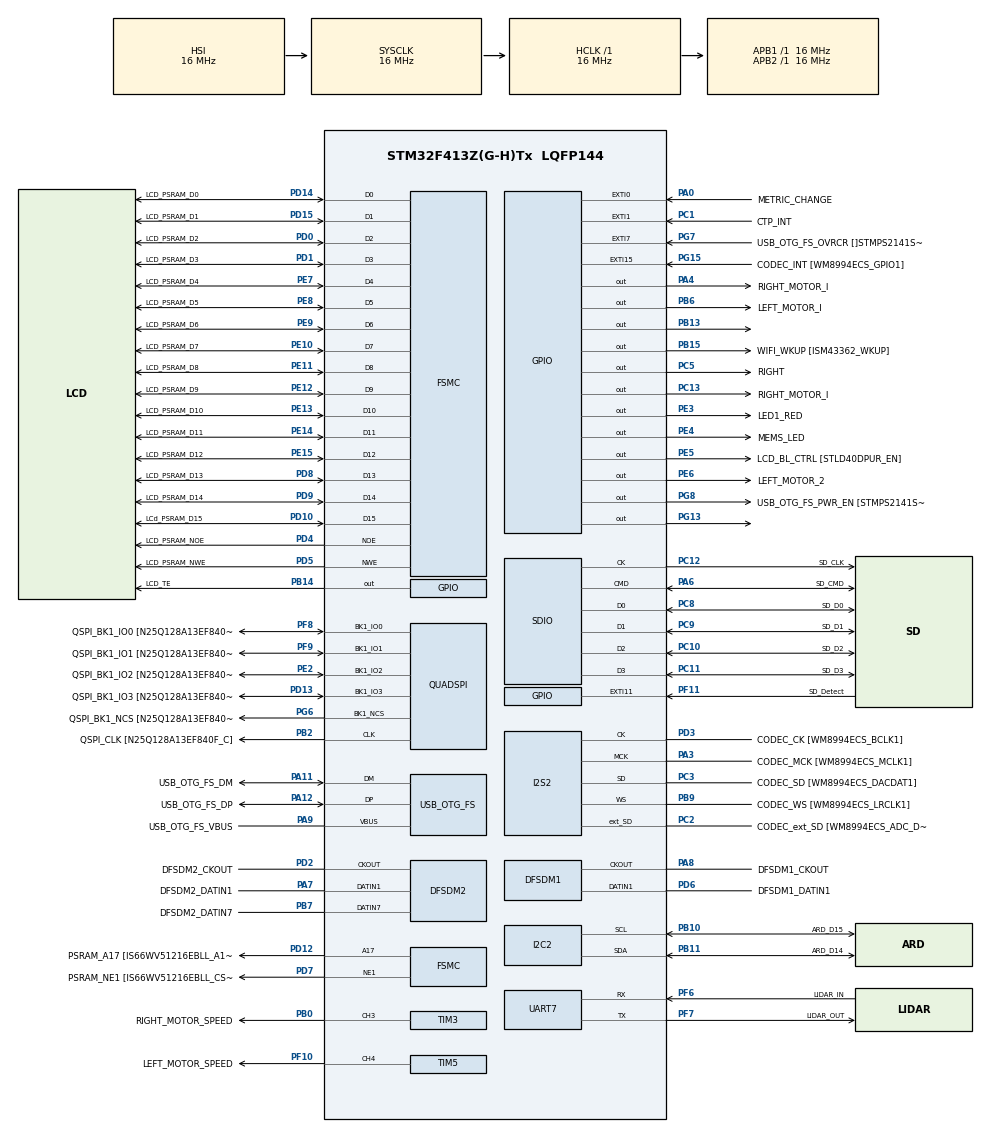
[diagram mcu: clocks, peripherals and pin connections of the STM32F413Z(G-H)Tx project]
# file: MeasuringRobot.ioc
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Dma.Request0=UART7_RX
Dma.UART7_RX.0.Direction=DMA_PERIPH_TO_MEMORY
Dma.UART7_RX.0.FIFOMode=DMA_FIFOMODE_DISABLE
Dma.UART7_RX.0.Instance=DMA1_Stream3
Dma.UART7_RX.0.MemDataAlignment=DMA_MDATAALIGN_BYTE
Dma.UART7_RX.0.MemInc=DMA_MINC_ENABLE
Dma.UART7_RX.0.Mode=DMA_NORMAL
Dma.UART7_RX.0.PeriphDataAlignment=DMA_PDATAALIGN_BYTE
Dma.UART7_RX.0.PeriphInc=DMA_PINC_DISABLE
Dma.UART7_RX.0.Priority=DMA_PRIORITY_LOW
FREERTOS.Tasks01=MetricChange,24,128,MetricChangeTask,Default,NULL,Dynamic,NULL,NULL;Motor,24,128,MotorTask,Default,NULL,Dynamic,NULL,NULL;Lidar,24,128,LidarTask,Default,NULL,Dynamic,NULL,NULL;LCD,24,128,LCDTask,Default,NULL,Dynamic,NULL,NULL
I2S2.ErrorAudioFreq=1.72 %
I2S2.FullDuplexMode=I2S_FULLDUPLEXMODE_ENABLE
I2S2.Instance=SPI$Index
I2S2.RealAudioFreq=8.138 KHz
I2S2.VirtualMode=I2S_MODE_MASTER
Mcu.Family=STM32F4
Mcu.Name=STM32F413Z(G-H)Tx
Mcu.Package=LQFP144
NVIC.DMA1_Stream3_IRQn=true\:0\:0\:false\:false\:true\:true\:false\:true
NVIC.EXTI0_IRQn=true\:0\:0\:false\:false\:true\:false\:true\:true
NVIC.OTG_FS_IRQn=true\:0\:0\:false\:false\:true\:false\:true\:true
NVIC.PriorityGroup=NVIC_PRIORITYGROUP_4
NVIC.TIM6_DAC_IRQn=true\:0\:0\:false\:false\:true\:false\:false\:true
NVIC.TimeBase=TIM6_DAC_IRQn
NVIC.TimeBaseIP=TIM6
PA0.GPIO_Label=METRIC_CHANGE
PA0.Signal=GPXTI0
PA10.GPIO_Label=USB_OTG_FS_ID
PA10.Signal=USB_OTG_FS_ID
PA11.GPIO_Label=USB_OTG_FS_DM
PA11.Mode=Host_Only
PA11.Signal=USB_OTG_FS_DM
PA12.GPIO_Label=USB_OTG_FS_DP
PA12.Mode=Host_Only
PA12.Signal=USB_OTG_FS_DP
PA13.GPIO_Label=STLINK_JTMS_SWDIO
PA13.Mode=Serial_Wire
PA13.Signal=SYS_JTMS-SWDIO
PA14.GPIO_Label=STLINK_JTMS_SWCLK
PA14.Mode=Serial_Wire
PA14.Signal=SYS_JTCK-SWCLK
PA15.GPIO_Label=ARD_D10
PA15.Signal=S_TIM2_CH1_ETR
PA3.GPIO_Label=CODEC_MCK [WM8994ECS_MCLK1]
PA3.Mode=Master_Clock_Activated
PA3.Signal=I2S2_MCK
PA4.GPIO_Label=RIGHT_MOTOR_I
PA4.Signal=GPIO_Output
PA5.GPIO_Label=ARD_A3
PA5.Signal=ADCx_IN5
PA6.GPIO_Label=SD_CMD
PA6.Mode=SD_4_bits_Wide_bus
PA6.Signal=SDIO_CMD
PA7.GPIO_Label=DFSDM2_DATIN1
PA7.Signal=S_DATAIN1DFSDM2
PA8.GPIO_Label=DFSDM1_CKOUT
PA8.Signal=S_CKOUTDFSDM1
PA9.GPIO_Label=USB_OTG_FS_VBUS
PA9.Mode=Activate_VBUS
PA9.Signal=USB_OTG_FS_VBUS
PB0.GPIO_Label=RIGHT_MOTOR_SPEED
PB0.Signal=S_TIM3_CH3
PB1.GPIO_Label=ARD_A4
PB1.Signal=ADCx_IN9
PB10.GPIO_Label=ARD_D15
PB10.Mode=I2C
PB10.Signal=I2C2_SCL
PB11.GPIO_Label=ARD_D14
PB11.Mode=I2C
PB11.Signal=I2C2_SDA
PB12.GPIO_Label=ARD_D13 [ISM43362_SCK]
PB12.Signal=SPI3_SCK
PB13.Signal=GPIO_Output
PB14.GPIO_Label=LCD_TE
PB14.Signal=GPIO_Output
PB15.GPIO_Label=WIFI_WKUP [ISM43362_WKUP]
PB15.Signal=GPIO_Output
PB2.GPIO_Label=QSPI_CLK [N25Q128A13EF840F_C]
PB2.Mode=Single Bank 1
PB2.Signal=QUADSPI_CLK
PB3.GPIO_Label=STLINK_JTDO_SWCLK
PB3.Signal=SYS_JTDO-SWO
PB4.GPIO_Label=ARD_D12 [ISM43362_MISO]
PB4.Signal=SPI3_MISO
PB5.GPIO_Label=ARD_D11 [ISM43362_MOSI]
PB5.Signal=SPI3_MOSI
PB6.GPIO_Label=LEFT_MOTOR_I
PB6.Signal=GPIO_Output
PB7.GPIO_Label=DFSDM2_DATIN7
PB7.Signal=S_DATAIN7DFSDM2
PB8.GPIO_Label=ARD_D9
PB8.Signal=S_TIM4_CH3
PB9.GPIO_Label=CODEC_WS [WM8994ECS_LRCLK1]
PB9.Mode=Full_Duplex_Master
PB9.Signal=I2S2_WS
PC0.GPIO_Label=ARD_A0
PC0.Signal=ADCx_IN10
PC1.GPIO_Label=CTP_INT
PC1.Signal=GPXTI1
PC10.GPIO_Label=SD_D2
PC10.Mode=SD_4_bits_Wide_bus
PC10.Signal=SDIO_D2
PC11.GPIO_Label=SD_D3
PC11.Mode=SD_4_bits_Wide_bus
PC11.Signal=SDIO_D3
PC12.GPIO_Label=SD_CLK
PC12.Mode=SD_4_bits_Wide_bus
PC12.Signal=SDIO_CK
PC13.GPIO_Label=RIGHT_MOTOR_I
PC13.Signal=GPIO_Output
PC14-OSC32_IN.GPIO_Label=OSC32_IN
PC14-OSC32_IN.Mode=LSE-External-Oscillator
PC14-OSC32_IN.Signal=RCC_OSC32_IN
PC15-OSC32_OUT.GPIO_Label=OSC32_OUT
PC15-OSC32_OUT.Mode=LSE-External-Oscillator
PC15-OSC32_OUT.Signal=RCC_OSC32_OUT
PC2.GPIO_Label=CODEC_ext_SD [WM8994ECS_ADC_DAT1]
PC2.Mode=Full_Duplex_Master
PC2.Signal=I2S2_ext_SD
PC3.GPIO_Label=CODEC_SD [WM8994ECS_DACDAT1]
PC3.Mode=Full_Duplex_Master
PC3.Signal=I2S2_SD
PC4.GPIO_Label=ARD_A5
PC4.Signal=ADCx_IN14
PC5.GPIO_Label=RIGHT
PC5.Signal=GPIO_Output
PC6.GPIO_Label=I2CFMP1_SCL [WM8994ECS_CLK]
PC6.Signal=FMPI2C1_SCL
PC7.GPIO_Label=I2CFMP_SDA [WM8994ECS_SDA]
PC7.Signal=FMPI2C1_SDA
PC8.GPIO_Label=SD_D0
PC8.Mode=SD_4_bits_Wide_bus
PC8.Signal=SDIO_D0
PC9.GPIO_Label=SD_D1
PC9.Mode=SD_4_bits_Wide_bus
PC9.Signal=SDIO_D1
PD0.GPIO_Label=LCD_PSRAM_D2
PD0.Signal=FSMC_D2_DA2
PD1.GPIO_Label=LCD_PSRAM_D3
PD1.Signal=FSMC_D3_DA3
PD10.GPIO_Label=LCd_PSRAM_D15
PD10.Signal=FSMC_D15_DA15
PD11.GPIO_Label=PSRAM_A16 [IS66WV51216EBLL_A16]
PD11.Signal=FSMC_A16
PD12.GPIO_Label=PSRAM_A17 [IS66WV51216EBLL_A17]
PD12.Signal=FSMC_A17
PD13.GPIO_Label=QSPI_BK1_IO3 [N25Q128A13EF840F_DQ3]
PD13.Mode=Single Bank 1
PD13.Signal=QUADSPI_BK1_IO3
PD14.GPIO_Label=LCD_PSRAM_D0
PD14.Signal=FSMC_D0_DA0
PD15.GPIO_Label=LCD_PSRAM_D1
PD15.Signal=FSMC_D1_DA1
PD2.GPIO_Label=DFSDM2_CKOUT
PD2.Signal=S_CKOUTDFSDM2
PD3.GPIO_Label=CODEC_CK [WM8994ECS_BCLK1]
PD3.Mode=Full_Duplex_Master
PD3.Signal=I2S2_CK
PD4.GPIO_Label=LCD_PSRAM_NOE
PD4.Signal=FSMC_NOE
PD5.GPIO_Label=LCD_PSRAM_NWE
PD5.Signal=FSMC_NWE
PD6.GPIO_Label=DFSDM1_DATIN1
PD6.Signal=S_DATAIN1DFSDM1
PD7.GPIO_Label=PSRAM_NE1 [IS66WV51216EBLL_CS1]
PD7.Mode=NorPsramChipSelect1_1
PD7.Signal=FSMC_NE1
PD8.GPIO_Label=LCD_PSRAM_D13
PD8.Signal=FSMC_D13_DA13
PD9.GPIO_Label=LCD_PSRAM_D14
PD9.Signal=FSMC_D14_DA14
PE0.GPIO_Label=PSRAM_NBL0 [IS66WV51216EBLL_LB]
PE0.Signal=FSMC_NBL0
PE1.GPIO_Label=PSRAM_NBL1 [IS66WV51216EBLL_UB]
PE1.Signal=FSMC_NBL1
PE10.GPIO_Label=LCD_PSRAM_D7
PE10.Signal=FSMC_D7_DA7
PE11.GPIO_Label=LCD_PSRAM_D8
PE11.Signal=FSMC_D8_DA8
PE12.GPIO_Label=LCD_PSRAM_D9
PE12.Signal=FSMC_D9_DA9
PE13.GPIO_Label=LCD_PSRAM_D10
PE13.Signal=FSMC_D10_DA10
PE14.GPIO_Label=LCD_PSRAM_D11
PE14.Signal=FSMC_D11_DA11
PE15.GPIO_Label=LCD_PSRAM_D12
PE15.Signal=FSMC_D12_DA12
PE2.GPIO_Label=QSPI_BK1_IO2 [N25Q128A13EF840F_DQ2]
PE2.Mode=Single Bank 1
PE2.Signal=QUADSPI_BK1_IO2
PE3.GPIO_Label=LED1_RED
PE3.Signal=GPIO_Output
PE4.GPIO_Label=MEMS_LED
PE4.Signal=GPIO_Output
PE5.GPIO_Label=LCD_BL_CTRL [STLD40DPUR_EN]
PE5.Signal=GPIO_Output
PE6.GPIO_Label=LEFT_MOTOR_2
PE6.Signal=GPIO_Output
PE7.GPIO_Label=LCD_PSRAM_D4
PE7.Signal=FSMC_D4_DA4
PE8.GPIO_Label=LCD_PSRAM_D5
PE8.Signal=FSMC_D5_DA5
PE9.GPIO_Label=LCD_PSRAM_D6
PE9.Signal=FSMC_D6_DA6
PF0.GPIO_Label=PSRAM_A0 [IS66WV51216EBLL_A0]
PF0.Signal=FSMC_A0
PF1.GPIO_Label=PSRAM_A1 [IS66WV51216EBLL_A1]
PF1.Signal=FSMC_A1
PF10.GPIO_Label=LEFT_MOTOR_SPEED
PF10.Signal=S_TIM5_CH4
PF11.GPIO_Label=SD_Detect
PF11.Signal=GPXTI11
PF12.GPIO_Label=PSRAM_A6 [IS66WV51216EBLL_A6]
PF12.Signal=FSMC_A6
PF13.GPIO_Label=PSRAM_A7 [IS66WV51216EBLL_A7]
PF13.Signal=FSMC_A7
PF14.GPIO_Label=PSRAM_A8 [IS66WV51216EBLL_A8]
PF14.Signal=FSMC_A8
PF15.GPIO_Label=PSRAM_A9 [IS66WV51216EBLL_A9]
PF15.Signal=FSMC_A9
PF2.GPIO_Label=PSRAM_A2 [IS66WV51216EBLL_A2]
PF2.Signal=FSMC_A2
PF3.GPIO_Label=PSRAM_A3 [IS66WV51216EBLL_A3]
PF3.Signal=FSMC_A3
PF4.GPIO_Label=PSRAM_A4 [IS66WV51216EBLL_A4]
PF4.Signal=FSMC_A4
PF5.GPIO_Label=PSRAM_A5 [IS66WV51216EBLL_A5]
PF5.Signal=FSMC_A5
PF6.GPIO_Label=LIDAR_IN
PF6.Mode=Asynchronous
PF6.Signal=UART7_RX
PF7.GPIO_Label=LIDAR_OUT
PF7.Mode=Asynchronous
PF7.Signal=UART7_TX
PF8.GPIO_Label=QSPI_BK1_IO0 [N25Q128A13EF840F_DQ0]
PF8.Mode=Single Bank 1
PF8.Signal=QUADSPI_BK1_IO0
PF9.GPIO_Label=QSPI_BK1_IO1 [N25Q128A13EF840F_DQ1]
PF9.Mode=Single Bank 1
PF9.Signal=QUADSPI_BK1_IO1
PG0.GPIO_Label=PSRAM_A10 [IS66WV51216EBLL_A10]
PG0.Signal=FSMC_A10
PG1.GPIO_Label=PSRAM_A11 [IS66WV51216EBLL_A11]
PG1.Signal=FSMC_A11
PG13.Signal=GPIO_Output
PG14.Signal=USART6_TX
PG15.GPIO_Label=CODEC_INT [WM8994ECS_GPIO1]
PG15.Signal=GPXTI15
PG2.GPIO_Label=PSRAM_A12 [IS66WV51216EBLL_A12]
PG2.Signal=FSMC_A12
PG3.GPIO_Label=PSRAM_A13 [IS66WV51216EBLL_A13]
PG3.Signal=FSMC_A13
PG4.GPIO_Label=PSRAM_A14 [IS66WV51216EBLL_A14]
PG4.Signal=FSMC_A14
PG5.GPIO_Label=PSRAM_A15 [IS66WV51216EBLL_A15]
PG5.Signal=FSMC_A15
PG6.GPIO_Label=QSPI_BK1_NCS [N25Q128A13EF840F_S]
PG6.Mode=Single Bank 1
PG6.Signal=QUADSPI_BK1_NCS
PG7.GPIO_Label=USB_OTG_FS_OVRCR []STMPS2141STR_FAULT]
PG7.Signal=GPXTI7
PG8.GPIO_Label=USB_OTG_FS_PWR_EN [STMPS2141STR_EN]
PG8.Signal=GPIO_Output
PG9.Signal=USART6_RX
PH0\ -\ OSC_IN.GPIO_Label=STLK_MCO
PH0\ -\ OSC_IN.Mode=HSE-External-Oscillator
PH0\ -\ OSC_IN.Signal=RCC_OSC_IN
PH1\ -\ OSC_OUT.Mode=HSE-External-Oscillator
PH1\ -\ OSC_OUT.Signal=RCC_OSC_OUT
ProjectManager.HeapSize=0x200
ProjectManager.StackSize=0x400
ProjectManager.TargetToolchain=STM32CubeIDE
RCC.AHBFreq_Value=16000000
RCC.APB1Freq_Value=16000000
RCC.APB1TimFreq_Value=16000000
RCC.APB2Freq_Value=16000000
RCC.APB2TimFreq_Value=16000000
RCC.CortexFreq_Value=16000000
RCC.HCLKFreq_Value=16000000
RCC.PLLI2SM=12
RCC.PLLI2SN=50
RCC.PLLM=15
RCC.PLLN=144
RCC.PLLQ=5
RCC.SDIOCLockSelection=RCC_SDIOCLKSOURCE_SYSCLK
RCC.SYSCLKFreq_VALUE=16000000
RCC.USBFreq_Value=48000000
RCC.VCOOutputFreq_Value=240000000
SH.ADCx_IN10.0=ADC1_IN10
SH.ADCx_IN14.0=ADC1_IN14
SH.ADCx_IN5.0=ADC1_IN5
SH.ADCx_IN9.0=ADC1_IN9
SH.FSMC_A0.0=FSMC_A0
SH.FSMC_A1.0=FSMC_A1
SH.FSMC_A10.0=FSMC_A10
SH.FSMC_A11.0=FSMC_A11
SH.FSMC_A12.0=FSMC_A12
SH.FSMC_A13.0=FSMC_A13
SH.FSMC_A14.0=FSMC_A14
SH.FSMC_A15.0=FSMC_A15
SH.FSMC_A16.0=FSMC_A16
SH.FSMC_A17.0=FSMC_A17,A17_1
SH.FSMC_A2.0=FSMC_A2
SH.FSMC_A3.0=FSMC_A3
SH.FSMC_A4.0=FSMC_A4
SH.FSMC_A5.0=FSMC_A5
SH.FSMC_A6.0=FSMC_A6
SH.FSMC_A7.0=FSMC_A7
SH.FSMC_A8.0=FSMC_A8
SH.FSMC_A9.0=FSMC_A9
SH.FSMC_D0_DA0.0=FSMC_D0,16b-d1
SH.FSMC_D10_DA10.0=FSMC_D10,16b-d1
SH.FSMC_D11_DA11.0=FSMC_D11,16b-d1
SH.FSMC_D12_DA12.0=FSMC_D12,16b-d1
SH.FSMC_D13_DA13.0=FSMC_D13,16b-d1
SH.FSMC_D14_DA14.0=FSMC_D14,16b-d1
SH.FSMC_D15_DA15.0=FSMC_D15,16b-d1
SH.FSMC_D1_DA1.0=FSMC_D1,16b-d1
SH.FSMC_D2_DA2.0=FSMC_D2,16b-d1
SH.FSMC_D3_DA3.0=FSMC_D3,16b-d1
SH.FSMC_D4_DA4.0=FSMC_D4,16b-d1
SH.FSMC_D5_DA5.0=FSMC_D5,16b-d1
SH.FSMC_D6_DA6.0=FSMC_D6,16b-d1
SH.FSMC_D7_DA7.0=FSMC_D7,16b-d1
SH.FSMC_D8_DA8.0=FSMC_D8,16b-d1
SH.FSMC_D9_DA9.0=FSMC_D9,16b-d1
SH.FSMC_NBL0.0=FSMC_NBL0
SH.FSMC_NBL1.0=FSMC_NBL1
SH.FSMC_NOE.0=FSMC_NOE,Lcd1
SH.FSMC_NWE.0=FSMC_NWE,Lcd1
SH.S_CKOUTDFSDM1.0=DFSDM1_CKOUT,CKOUT
SH.S_CKOUTDFSDM2.0=DFSDM2_CKOUT,CKOUT
SH.S_DATAIN1DFSDM1.0=DFSDM1_DATIN1,Manchester_input_from_ch1
SH.S_DATAIN1DFSDM2.0=DFSDM2_DATIN1,Manchester_input_from_ch1
SH.S_DATAIN7DFSDM2.0=DFSDM2_DATIN7,Manchester_input_from_ch7
SH.S_TIM2_CH1_ETR.0=TIM2_CH1
SH.S_TIM3_CH3.0=TIM3_CH3,PWM Generation3 CH3
SH.S_TIM4_CH3.0=TIM4_CH3
SH.S_TIM5_CH4.0=TIM5_CH4,PWM Generation4 CH4
TIM3.Channel-PWM\ Generation3\ CH3=TIM_CHANNEL_3
TIM3.Period=1000
TIM3.Prescaler=16
TIM3.Pulse-PWM\ Generation3\ CH3=500
TIM5.Channel-PWM\ Generation4\ CH4=TIM_CHANNEL_4
TIM5.Period=1000
TIM5.Prescaler=16
TIM5.Pulse-PWM\ Generation4\ CH4=500
UART7.OverSampling=UART_OVERSAMPLING_16
UART7.VirtualMode=Asynchronous
UART7.WordLength=WORDLENGTH_8B
USB_HOST.BSP.number=1
USB_HOST.USBH_HandleTypeDef=hUsbHostFS
USB_HOST.USBH_USE_OS-CDC_FS=0
USB_HOST.VirtualModeFS=Cdc
USB_HOST0.BSP.STBoard=false
USB_HOST0.BSP.api=Unknown
USB_HOST0.BSP.i2caddr=0
USB_HOST0.BSP.i2creg=0
USB_HOST0.BSP.instance=PG8
USB_HOST0.BSP.ip=GPIO
USB_HOST0.BSP.mode=Output
USB_HOST0.BSP.name=Drive_VBUS_FS
USB_HOST0.BSP.solution=PG8
USB_OTG_FS.VirtualMode=Host_Only
USB_OTG_FS.phy_itface=HCD_PHY_EMBEDDED
VP_FREERTOS_VS_CMSIS_V2.Mode=CMSIS_V2
VP_SYS_VS_tim6.Mode=TIM6
VP_TIM3_VS_ClockSourceINT.Mode=Internal
VP_TIM5_VS_ClockSourceINT.Mode=Internal
VP_USB_HOST_VS_USB_HOST_CDC_FS.Mode=CDC_FS
board=STM32F413H-DISCO

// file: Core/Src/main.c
/* USER CODE BEGIN Header */
/**
 ******************************************************************************
 * @file           : main.c
 * @brief          : Main program body
 ******************************************************************************
 * @attention
 *
 * <h2><center>&copy; Copyright (c) 2022 STMicroelectronics.
 * All rights reserved.</center></h2>
 *
 * This software component is licensed by ST under Ultimate Liberty license
 * SLA0044, the "License"; You may not use this file except in compliance with
 * the License. You may obtain a copy of the License at:
 *                             www.st.com/SLA0044
 *
 ******************************************************************************
 */
/* USER CODE END Header */
#include "main.h"
#include "cmsis_os.h"
#include "usb_host.h"

/* USER CODE BEGIN Includes */
#include "stm32F413h_discovery_lcd.h"
#include "math.h"
#include "stdlib.h"
#include "stdio.h"
/* USER CODE END Includes */

DFSDM_Channel_HandleTypeDef hdfsdm1_channel1;
DFSDM_Channel_HandleTypeDef hdfsdm2_channel1;
DFSDM_Channel_HandleTypeDef hdfsdm2_channel7;

I2C_HandleTypeDef hi2c2;

I2S_HandleTypeDef hi2s2;

QSPI_HandleTypeDef hqspi;

SD_HandleTypeDef hsd;

TIM_HandleTypeDef htim3;
TIM_HandleTypeDef htim5;

UART_HandleTypeDef huart7;
DMA_HandleTypeDef hdma_uart7_rx;

SRAM_HandleTypeDef hsram1;

/* Definitions for MetricChange */
osThreadId_t MetricChangeHandle;
const osThreadAttr_t MetricChange_attributes = { .name = "MetricChange",
		.priority = (osPriority_t) osPriorityNormal, .stack_size = 128 * 4 };
/* Definitions for Motor */
osThreadId_t MotorHandle;
const osThreadAttr_t Motor_attributes = { .name = "Motor", .priority =
		(osPriority_t) osPriorityNormal, .stack_size = 128 * 4 };
/* Definitions for Lidar */
osThreadId_t LidarHandle;
const osThreadAttr_t Lidar_attributes = { .name = "Lidar", .priority =
		(osPriority_t) osPriorityNormal, .stack_size = 128 * 4 };
/* Definitions for LCD */
osThreadId_t LCDHandle;
const osThreadAttr_t LCD_attributes = { .name = "LCD", .priority =
		(osPriority_t) osPriorityNormal, .stack_size = 128 * 4 };
/* USER CODE BEGIN PV */
#define MOTOR_TASK_RATE 75
#define LIDAR_TASK_RATE 75
#define LCD_TASK_RATE 200
#define METRIC_TASK_RATE 300
#define CM_TO_INCH 0.393701
#define CM_TO_FEET 0.0328084
#define CM_TO_METER 0.01
uint8_t lidar_rx_buffer[9];
//5A 06 03 00 00 00
uint8_t lidar_tx_buffer_init[] = { 0x5A, 0x06, 0x03, 0x01, 0x00, 0x00 };
//5A 05 05 02 00
uint8_t lidar_tx_buffer[] = { 0x5A, 0x04, 0x04, 0x00 };
extern uint8_t metric_change = 0;
uint8_t curr_metric = 0;
uint8_t distance_high;
uint8_t distance_low;
double metric_multiplier = 1;
char metric[10] = "cm";
/* USER CODE END PV */

void SystemClock_Config(void);
static void MX_GPIO_Init(void);
static void MX_DMA_Init(void);
static void MX_DFSDM1_Init(void);
static void MX_DFSDM2_Init(void);
static void MX_FSMC_Init(void);
static void MX_I2S2_Init(void);
static void MX_SDIO_SD_Init(void);
static void MX_UART7_Init(void);
static void MX_I2C2_Init(void);
static void MX_QUADSPI_Init(void);
static void MX_TIM3_Init(void);
static void MX_TIM5_Init(void);
void MetricChangeTask(void *argument);
void MotorTask(void *argument);
void LidarTask(void *argument);
void LCDTask(void *argument);

int main(void) {

	/* MCU Configuration--------------------------------------------------------*/

	/* Reset of all peripherals, Initializes the Flash interface and the Systick. */
	HAL_Init();

	/* Configure the system clock */
	SystemClock_Config();

	/* Initialize all configured peripherals */
	MX_GPIO_Init();
	MX_DMA_Init();
	MX_DFSDM1_Init();
	MX_DFSDM2_Init();
	MX_FSMC_Init();
	MX_I2S2_Init();
	MX_SDIO_SD_Init();
	MX_UART7_Init();
	MX_I2C2_Init();
	MX_QUADSPI_Init();
	MX_TIM3_Init();
	MX_TIM5_Init();
	/* USER CODE BEGIN 2 */
	BSP_LCD_Init();
	BSP_LCD_Clear(LCD_COLOR_WHITE);
	BSP_LCD_SetFont(&Font16);
	BSP_LCD_SetBackColor(LCD_COLOR_WHITE);
	BSP_LCD_SetTextColor(LCD_COLOR_BLACK);

	HAL_UART_Transmit(&huart7, lidar_tx_buffer_init, 6, 50);
	/* USER CODE END 2 */

	/* Init scheduler */
	osKernelInitialize();

	/* Create the thread(s) */
	/* creation of MetricChange */
	MetricChangeHandle = osThreadNew(MetricChangeTask, NULL,
			&MetricChange_attributes);

	/* creation of Motor */
	MotorHandle = osThreadNew(MotorTask, NULL, &Motor_attributes);

	/* creation of Lidar */
	LidarHandle = osThreadNew(LidarTask, NULL, &Lidar_attributes);

	/* creation of LCD */
	LCDHandle = osThreadNew(LCDTask, NULL, &LCD_attributes);

	/* Start scheduler */
	osKernelStart();

	/* We should never get here as control is now taken by the scheduler */
	/* Infinite loop */
	while (1) {

	}
}

void SystemClock_Config(void) {
	RCC_OscInitTypeDef RCC_OscInitStruct = { 0 };
	RCC_ClkInitTypeDef RCC_ClkInitStruct = { 0 };
	RCC_PeriphCLKInitTypeDef PeriphClkInitStruct = { 0 };

	/** Configure the main internal regulator output voltage
	 */
	__HAL_RCC_PWR_CLK_ENABLE();
	__HAL_PWR_VOLTAGESCALING_CONFIG(PWR_REGULATOR_VOLTAGE_SCALE1);
	/** Initializes the RCC Oscillators according to the specified parameters
	 * in the RCC_OscInitTypeDef structure.
	 */
	RCC_OscInitStruct.OscillatorType = RCC_OSCILLATORTYPE_HSI
			| RCC_OSCILLATORTYPE_HSE;
	RCC_OscInitStruct.HSEState = RCC_HSE_ON;
	RCC_OscInitStruct.HSIState = RCC_HSI_ON;
	RCC_OscInitStruct.HSICalibrationValue = RCC_HSICALIBRATION_DEFAULT;
	RCC_OscInitStruct.PLL.PLLState = RCC_PLL_ON;
	RCC_OscInitStruct.PLL.PLLSource = RCC_PLLSOURCE_HSE;
	RCC_OscInitStruct.PLL.PLLM = 15;
	RCC_OscInitStruct.PLL.PLLN = 144;
	RCC_OscInitStruct.PLL.PLLP = RCC_PLLP_DIV2;
	RCC_OscInitStruct.PLL.PLLQ = 5;
	RCC_OscInitStruct.PLL.PLLR = 2;
	if (HAL_RCC_OscConfig(&RCC_OscInitStruct) != HAL_OK) {
		Error_Handler();
	}
	/** Initializes the CPU, AHB and APB buses clocks
	 */
	RCC_ClkInitStruct.ClockType = RCC_CLOCKTYPE_HCLK | RCC_CLOCKTYPE_SYSCLK
			| RCC_CLOCKTYPE_PCLK1 | RCC_CLOCKTYPE_PCLK2;
	RCC_ClkInitStruct.SYSCLKSource = RCC_SYSCLKSOURCE_HSI;
	RCC_ClkInitStruct.AHBCLKDivider = RCC_SYSCLK_DIV1;
	RCC_ClkInitStruct.APB1CLKDivider = RCC_HCLK_DIV1;
	RCC_ClkInitStruct.APB2CLKDivider = RCC_HCLK_DIV1;

	if (HAL_RCC_ClockConfig(&RCC_ClkInitStruct, FLASH_LATENCY_0) != HAL_OK) {
		Error_Handler();
	}
	PeriphClkInitStruct.PeriphClockSelection = RCC_PERIPHCLK_I2S_APB1
			| RCC_PERIPHCLK_DFSDM1 | RCC_PERIPHCLK_SDIO | RCC_PERIPHCLK_CLK48;
	PeriphClkInitStruct.PLLI2S.PLLI2SN = 50;
	PeriphClkInitStruct.PLLI2S.PLLI2SM = 12;
	PeriphClkInitStruct.PLLI2S.PLLI2SR = 2;
	PeriphClkInitStruct.PLLI2S.PLLI2SQ = 2;
	PeriphClkInitStruct.Clk48ClockSelection = RCC_CLK48CLKSOURCE_PLLQ;
	PeriphClkInitStruct.Dfsdm1ClockSelection = RCC_DFSDM1CLKSOURCE_APB2;
	PeriphClkInitStruct.SdioClockSelection = RCC_SDIOCLKSOURCE_SYSCLK;
	PeriphClkInitStruct.PLLI2SSelection = RCC_PLLI2SCLKSOURCE_PLLSRC;
	PeriphClkInitStruct.I2sApb1ClockSelection = RCC_I2SAPB1CLKSOURCE_PLLI2S;
	if (HAL_RCCEx_PeriphCLKConfig(&PeriphClkInitStruct) != HAL_OK) {
		Error_Handler();
	}
}

static void MX_DFSDM1_Init(void) {

	hdfsdm1_channel1.Instance = DFSDM1_Channel1;
	hdfsdm1_channel1.Init.OutputClock.Activation = ENABLE;
	hdfsdm1_channel1.Init.OutputClock.Selection =
	DFSDM_CHANNEL_OUTPUT_CLOCK_SYSTEM;
	hdfsdm1_channel1.Init.OutputClock.Divider = 2;
	hdfsdm1_channel1.Init.Input.Multiplexer = DFSDM_CHANNEL_EXTERNAL_INPUTS;
	hdfsdm1_channel1.Init.Input.DataPacking = DFSDM_CHANNEL_STANDARD_MODE;
	hdfsdm1_channel1.Init.Input.Pins = DFSDM_CHANNEL_SAME_CHANNEL_PINS;
	hdfsdm1_channel1.Init.SerialInterface.Type =
	DFSDM_CHANNEL_MANCHESTER_RISING;
	hdfsdm1_channel1.Init.SerialInterface.SpiClock =
	DFSDM_CHANNEL_SPI_CLOCK_EXTERNAL;
	hdfsdm1_channel1.Init.Awd.FilterOrder = DFSDM_CHANNEL_FASTSINC_ORDER;
	hdfsdm1_channel1.Init.Awd.Oversampling = 1;
	hdfsdm1_channel1.Init.Offset = 0;
	hdfsdm1_channel1.Init.RightBitShift = 0x00;
	if (HAL_DFSDM_ChannelInit(&hdfsdm1_channel1) != HAL_OK) {
		Error_Handler();
	}

}

static void MX_DFSDM2_Init(void) {

	hdfsdm2_channel1.Instance = DFSDM2_Channel1;
	hdfsdm2_channel1.Init.OutputClock.Activation = ENABLE;
	hdfsdm2_channel1.Init.OutputClock.Selection =
	DFSDM_CHANNEL_OUTPUT_CLOCK_SYSTEM;
	hdfsdm2_channel1.Init.OutputClock.Divider = 2;
	hdfsdm2_channel1.Init.Input.Multiplexer = DFSDM_CHANNEL_EXTERNAL_INPUTS;
	hdfsdm2_channel1.Init.Input.DataPacking = DFSDM_CHANNEL_STANDARD_MODE;
	hdfsdm2_channel1.Init.Input.Pins = DFSDM_CHANNEL_SAME_CHANNEL_PINS;
	hdfsdm2_channel1.Init.SerialInterface.Type =
	DFSDM_CHANNEL_MANCHESTER_RISING;
	hdfsdm2_channel1.Init.SerialInterface.SpiClock =
	DFSDM_CHANNEL_SPI_CLOCK_EXTERNAL;
	hdfsdm2_channel1.Init.Awd.FilterOrder = DFSDM_CHANNEL_FASTSINC_ORDER;
	hdfsdm2_channel1.Init.Awd.Oversampling = 1;
	hdfsdm2_channel1.Init.Offset = 0;
	hdfsdm2_channel1.Init.RightBitShift = 0x00;
	if (HAL_DFSDM_ChannelInit(&hdfsdm2_channel1) != HAL_OK) {
		Error_Handler();
	}
	hdfsdm2_channel7.Instance = DFSDM2_Channel7;
	hdfsdm2_channel7.Init.OutputClock.Activation = ENABLE;
	hdfsdm2_channel7.Init.OutputClock.Selection =
	DFSDM_CHANNEL_OUTPUT_CLOCK_SYSTEM;
	hdfsdm2_channel7.Init.OutputClock.Divider = 2;
	hdfsdm2_channel7.Init.Input.Multiplexer = DFSDM_CHANNEL_EXTERNAL_INPUTS;
	hdfsdm2_channel7.Init.Input.DataPacking = DFSDM_CHANNEL_STANDARD_MODE;
	hdfsdm2_channel7.Init.Input.Pins = DFSDM_CHANNEL_SAME_CHANNEL_PINS;
	hdfsdm2_channel7.Init.SerialInterface.Type =
	DFSDM_CHANNEL_MANCHESTER_RISING;
	hdfsdm2_channel7.Init.SerialInterface.SpiClock =
	DFSDM_CHANNEL_SPI_CLOCK_EXTERNAL;
	hdfsdm2_channel7.Init.Awd.FilterOrder = DFSDM_CHANNEL_FASTSINC_ORDER;
	hdfsdm2_channel7.Init.Awd.Oversampling = 1;
	hdfsdm2_channel7.Init.Offset = 0;
	hdfsdm2_channel7.Init.RightBitShift = 0x00;
	if (HAL_DFSDM_ChannelInit(&hdfsdm2_channel7) != HAL_OK) {
		Error_Handler();
	}

}

static void MX_I2C2_Init(void) {

	hi2c2.Instance = I2C2;
	hi2c2.Init.ClockSpeed = 100000;
	hi2c2.Init.DutyCycle = I2C_DUTYCYCLE_2;
	hi2c2.Init.OwnAddress1 = 0;
	hi2c2.Init.AddressingMode = I2C_ADDRESSINGMODE_7BIT;
	hi2c2.Init.DualAddressMode = I2C_DUALADDRESS_DISABLE;
	hi2c2.Init.OwnAddress2 = 0;
	hi2c2.Init.GeneralCallMode = I2C_GENERALCALL_DISABLE;
	hi2c2.Init.NoStretchMode = I2C_NOSTRETCH_DISABLE;
	if (HAL_I2C_Init(&hi2c2) != HAL_OK) {
		Error_Handler();
	}

}

static void MX_I2S2_Init(void) {

	hi2s2.Instance = SPI2;
	hi2s2.Init.Mode = I2S_MODE_MASTER_TX;
	hi2s2.Init.Standard = I2S_STANDARD_PHILIPS;
	hi2s2.Init.DataFormat = I2S_DATAFORMAT_16B;
	hi2s2.Init.MCLKOutput = I2S_MCLKOUTPUT_ENABLE;
	hi2s2.Init.AudioFreq = I2S_AUDIOFREQ_8K;
	hi2s2.Init.CPOL = I2S_CPOL_LOW;
	hi2s2.Init.ClockSource = I2S_CLOCK_PLL;
	hi2s2.Init.FullDuplexMode = I2S_FULLDUPLEXMODE_ENABLE;
	if (HAL_I2S_Init(&hi2s2) != HAL_OK) {
		Error_Handler();
	}

}

static void MX_QUADSPI_Init(void) {

	/* QUADSPI parameter configuration*/
	hqspi.Instance = QUADSPI;
	hqspi.Init.ClockPrescaler = 255;
	hqspi.Init.FifoThreshold = 1;
	hqspi.Init.SampleShifting = QSPI_SAMPLE_SHIFTING_NONE;
	hqspi.Init.FlashSize = 1;
	hqspi.Init.ChipSelectHighTime = QSPI_CS_HIGH_TIME_1_CYCLE;
	hqspi.Init.ClockMode = QSPI_CLOCK_MODE_0;
	hqspi.Init.FlashID = QSPI_FLASH_ID_1;
	hqspi.Init.DualFlash = QSPI_DUALFLASH_DISABLE;
	if (HAL_QSPI_Init(&hqspi) != HAL_OK) {
		Error_Handler();
	}

}

static void MX_SDIO_SD_Init(void) {

	hsd.Instance = SDIO;
	hsd.Init.ClockEdge = SDIO_CLOCK_EDGE_RISING;
	hsd.Init.ClockBypass = SDIO_CLOCK_BYPASS_DISABLE;
	hsd.Init.ClockPowerSave = SDIO_CLOCK_POWER_SAVE_DISABLE;
	hsd.Init.BusWide = SDIO_BUS_WIDE_1B;
	hsd.Init.HardwareFlowControl = SDIO_HARDWARE_FLOW_CONTROL_DISABLE;
	hsd.Init.ClockDiv = 0;
	if (HAL_SD_Init(&hsd) != HAL_OK) {
		Error_Handler();
	}
	if (HAL_SD_ConfigWideBusOperation(&hsd, SDIO_BUS_WIDE_4B) != HAL_OK) {
		Error_Handler();
	}

}

static void MX_TIM3_Init(void) {

	TIM_ClockConfigTypeDef sClockSourceConfig = { 0 };
	TIM_MasterConfigTypeDef sMasterConfig = { 0 };
	TIM_OC_InitTypeDef sConfigOC = { 0 };

	htim3.Instance = TIM3;
	htim3.Init.Prescaler = 16;
	htim3.Init.CounterMode = TIM_COUNTERMODE_UP;
	htim3.Init.Period = 1000;
	htim3.Init.ClockDivision = TIM_CLOCKDIVISION_DIV1;
	htim3.Init.AutoReloadPreload = TIM_AUTORELOAD_PRELOAD_DISABLE;
	if (HAL_TIM_Base_Init(&htim3) != HAL_OK) {
		Error_Handler();
	}
	sClockSourceConfig.ClockSource = TIM_CLOCKSOURCE_INTERNAL;
	if (HAL_TIM_ConfigClockSource(&htim3, &sClockSourceConfig) != HAL_OK) {
		Error_Handler();
	}
	if (HAL_TIM_PWM_Init(&htim3) != HAL_OK) {
		Error_Handler();
	}
	sMasterConfig.MasterOutputTrigger = TIM_TRGO_RESET;
	sMasterConfig.MasterSlaveMode = TIM_MASTERSLAVEMODE_DISABLE;
	if (HAL_TIMEx_MasterConfigSynchronization(&htim3, &sMasterConfig)
			!= HAL_OK) {
		Error_Handler();
	}
	sConfigOC.OCMode = TIM_OCMODE_PWM1;
	sConfigOC.Pulse = 500;
	sConfigOC.OCPolarity = TIM_OCPOLARITY_HIGH;
	sConfigOC.OCFastMode = TIM_OCFAST_DISABLE;
	if (HAL_TIM_PWM_ConfigChannel(&htim3, &sConfigOC, TIM_CHANNEL_3)
			!= HAL_OK) {
		Error_Handler();
	}
	HAL_TIM_MspPostInit(&htim3);

}

static void MX_TIM5_Init(void) {

	TIM_ClockConfigTypeDef sClockSourceConfig = { 0 };
	TIM_MasterConfigTypeDef sMasterConfig = { 0 };
	TIM_OC_InitTypeDef sConfigOC = { 0 };

	htim5.Instance = TIM5;
	htim5.Init.Prescaler = 16;
	htim5.Init.CounterMode = TIM_COUNTERMODE_UP;
	htim5.Init.Period = 1000;
	htim5.Init.ClockDivision = TIM_CLOCKDIVISION_DIV1;
	htim5.Init.AutoReloadPreload = TIM_AUTORELOAD_PRELOAD_DISABLE;
	if (HAL_TIM_Base_Init(&htim5) != HAL_OK) {
		Error_Handler();
	}
	sClockSourceConfig.ClockSource = TIM_CLOCKSOURCE_INTERNAL;
	if (HAL_TIM_ConfigClockSource(&htim5, &sClockSourceConfig) != HAL_OK) {
		Error_Handler();
	}
	if (HAL_TIM_PWM_Init(&htim5) != HAL_OK) {
		Error_Handler();
	}
	sMasterConfig.MasterOutputTrigger = TIM_TRGO_RESET;
	sMasterConfig.MasterSlaveMode = TIM_MASTERSLAVEMODE_DISABLE;
	if (HAL_TIMEx_MasterConfigSynchronization(&htim5, &sMasterConfig)
			!= HAL_OK) {
		Error_Handler();
	}
	sConfigOC.OCMode = TIM_OCMODE_PWM1;
	sConfigOC.Pulse = 500;
	sConfigOC.OCPolarity = TIM_OCPOLARITY_HIGH;
	sConfigOC.OCFastMode = TIM_OCFAST_DISABLE;
	if (HAL_TIM_PWM_ConfigChannel(&htim5, &sConfigOC, TIM_CHANNEL_4)
			!= HAL_OK) {
		Error_Handler();
	}
	HAL_TIM_MspPostInit(&htim5);

}

static void MX_UART7_Init(void) {

	huart7.Instance = UART7;
	huart7.Init.BaudRate = 115200;
	huart7.Init.WordLength = UART_WORDLENGTH_8B;
	huart7.Init.StopBits = UART_STOPBITS_1;
	huart7.Init.Parity = UART_PARITY_NONE;
	huart7.Init.Mode = UART_MODE_TX_RX;
	huart7.Init.HwFlowCtl = UART_HWCONTROL_NONE;
	huart7.Init.OverSampling = UART_OVERSAMPLING_16;
	if (HAL_UART_Init(&huart7) != HAL_OK) {
		Error_Handler();
	}

}

static void MX_DMA_Init(void) {

	/* DMA controller clock enable */
	__HAL_RCC_DMA1_CLK_ENABLE();

	/* DMA interrupt init */
	/* DMA1_Stream3_IRQn interrupt configuration */
	HAL_NVIC_SetPriority(DMA1_Stream3_IRQn, 0, 0);
	HAL_NVIC_EnableIRQ(DMA1_Stream3_IRQn);

}

static void MX_GPIO_Init(void) {
	GPIO_InitTypeDef GPIO_InitStruct = { 0 };

	/* GPIO Ports Clock Enable */
	__HAL_RCC_GPIOE_CLK_ENABLE();
	__HAL_RCC_GPIOC_CLK_ENABLE();
	__HAL_RCC_GPIOF_CLK_ENABLE();
	__HAL_RCC_GPIOH_CLK_ENABLE();
	__HAL_RCC_GPIOA_CLK_ENABLE();
	__HAL_RCC_GPIOB_CLK_ENABLE();
	__HAL_RCC_GPIOG_CLK_ENABLE();
	__HAL_RCC_GPIOD_CLK_ENABLE();

	/*Configure GPIO pin Output Level */
	HAL_GPIO_WritePin(GPIOE,
	LED1_RED_Pin | MEMS_LED_Pin | LCD_BL_CTRL_Pin | LEFT_MOTOR_2_Pin,
			GPIO_PIN_RESET);

	/*Configure GPIO pin Output Level */
	HAL_GPIO_WritePin(GPIOC, RIGHT_MOTOR_I_Pin | RIGHT_Pin, GPIO_PIN_RESET);

	/*Configure GPIO pin Output Level */
	HAL_GPIO_WritePin(RIGHT_MOTOR_IA4_GPIO_Port, RIGHT_MOTOR_IA4_Pin,
			GPIO_PIN_RESET);

	/*Configure GPIO pin Output Level */
	HAL_GPIO_WritePin(GPIOB,
	GPIO_PIN_13 | LCD_TE_Pin | WIFI_WKUP_Pin | LEFT_MOTOR_I_Pin,
			GPIO_PIN_RESET);

	/*Configure GPIO pin Output Level */
	HAL_GPIO_WritePin(GPIOG, USB_OTG_FS_PWR_EN_Pin | GPIO_PIN_13,
			GPIO_PIN_RESET);

	/*Configure GPIO pins : LED1_RED_Pin MEMS_LED_Pin LCD_BL_CTRL_Pin LEFT_MOTOR_2_Pin */
	GPIO_InitStruct.Pin = LED1_RED_Pin | MEMS_LED_Pin | LCD_BL_CTRL_Pin
			| LEFT_MOTOR_2_Pin;
	GPIO_InitStruct.Mode = GPIO_MODE_OUTPUT_PP;
	GPIO_InitStruct.Pull = GPIO_NOPULL;
	GPIO_InitStruct.Speed = GPIO_SPEED_FREQ_LOW;
	HAL_GPIO_Init(GPIOE, &GPIO_InitStruct);

	/*Configure GPIO pins : RIGHT_MOTOR_I_Pin RIGHT_Pin */
	GPIO_InitStruct.Pin = RIGHT_MOTOR_I_Pin | RIGHT_Pin;
	GPIO_InitStruct.Mode = GPIO_MODE_OUTPUT_PP;
	GPIO_InitStruct.Pull = GPIO_NOPULL;
	GPIO_InitStruct.Speed = GPIO_SPEED_FREQ_LOW;
	HAL_GPIO_Init(GPIOC, &GPIO_InitStruct);

	/*Configure GPIO pins : ARD_A0_Pin ARD_A5_Pin */
	GPIO_InitStruct.Pin = ARD_A0_Pin | ARD_A5_Pin;
	GPIO_InitStruct.Mode = GPIO_MODE_ANALOG;
	GPIO_InitStruct.Pull = GPIO_NOPULL;
	HAL_GPIO_Init(GPIOC, &GPIO_InitStruct);

	/*Configure GPIO pin : CTP_INT_Pin */
	GPIO_InitStruct.Pin = CTP_INT_Pin;
	GPIO_InitStruct.Mode = GPIO_MODE_IT_RISING;
	GPIO_InitStruct.Pull = GPIO_NOPULL;
	HAL_GPIO_Init(CTP_INT_GPIO_Port, &GPIO_InitStruct);

	/*Configure GPIO pin : METRIC_CHANGE_Pin */
	GPIO_InitStruct.Pin = METRIC_CHANGE_Pin;
	GPIO_InitStruct.Mode = GPIO_MODE_IT_RISING;
	GPIO_InitStruct.Pull = GPIO_NOPULL;
	HAL_GPIO_Init(METRIC_CHANGE_GPIO_Port, &GPIO_InitStruct);

	/*Configure GPIO pin : RIGHT_MOTOR_IA4_Pin */
	GPIO_InitStruct.Pin = RIGHT_MOTOR_IA4_Pin;
	GPIO_InitStruct.Mode = GPIO_MODE_OUTPUT_PP;
	GPIO_InitStruct.Pull = GPIO_NOPULL;
	GPIO_InitStruct.Speed = GPIO_SPEED_FREQ_LOW;
	HAL_GPIO_Init(RIGHT_MOTOR_IA4_GPIO_Port, &GPIO_InitStruct);

	/*Configure GPIO pin : ARD_A3_Pin */
	GPIO_InitStruct.Pin = ARD_A3_Pin;
	GPIO_InitStruct.Mode = GPIO_MODE_ANALOG;
	GPIO_InitStruct.Pull = GPIO_NOPULL;
	HAL_GPIO_Init(ARD_A3_GPIO_Port, &GPIO_InitStruct);

	/*Configure GPIO pin : ARD_A4_Pin */
	GPIO_InitStruct.Pin = ARD_A4_Pin;
	GPIO_InitStruct.Mode = GPIO_MODE_ANALOG;
	GPIO_InitStruct.Pull = GPIO_NOPULL;
	HAL_GPIO_Init(ARD_A4_GPIO_Port, &GPIO_InitStruct);

	/*Configure GPIO pin : SD_Detect_Pin */
	GPIO_InitStruct.Pin = SD_Detect_Pin;
	GPIO_InitStruct.Mode = GPIO_MODE_IT_RISING;
	GPIO_InitStruct.Pull = GPIO_NOPULL;
	HAL_GPIO_Init(SD_Detect_GPIO_Port, &GPIO_InitStruct);

	/*Configure GPIO pin : ARD_D13_Pin */
	GPIO_InitStruct.Pin = ARD_D13_Pin;
	GPIO_InitStruct.Mode = GPIO_MODE_AF_PP;
	GPIO_InitStruct.Pull = GPIO_NOPULL;
	GPIO_InitStruct.Speed = GPIO_SPEED_FREQ_VERY_HIGH;
	GPIO_InitStruct.Alternate = GPIO_AF7_SPI3;
	HAL_GPIO_Init(ARD_D13_GPIO_Port, &GPIO_InitStruct);

	/*Configure GPIO pins : PB13 LCD_TE_Pin WIFI_WKUP_Pin LEFT_MOTOR_I_Pin */
	GPIO_InitStruct.Pin = GPIO_PIN_13 | LCD_TE_Pin | WIFI_WKUP_Pin
			| LEFT_MOTOR_I_Pin;
	GPIO_InitStruct.Mode = GPIO_MODE_OUTPUT_PP;
	GPIO_InitStruct.Pull = GPIO_NOPULL;
	GPIO_InitStruct.Speed = GPIO_SPEED_FREQ_LOW;
	HAL_GPIO_Init(GPIOB, &GPIO_InitStruct);

	/*Configure GPIO pins : USB_OTG_FS_OVRCR_Pin CODEC_INT_Pin */
	GPIO_InitStruct.Pin = USB_OTG_FS_OVRCR_Pin | CODEC_INT_Pin;
	GPIO_InitStruct.Mode = GPIO_MODE_IT_RISING;
	GPIO_InitStruct.Pull = GPIO_NOPULL;
	HAL_GPIO_Init(GPIOG, &GPIO_InitStruct);

	/*Configure GPIO pins : USB_OTG_FS_PWR_EN_Pin PG13 */
	GPIO_InitStruct.Pin = USB_OTG_FS_PWR_EN_Pin | GPIO_PIN_13;
	GPIO_InitStruct.Mode = GPIO_MODE_OUTPUT_PP;
	GPIO_InitStruct.Pull = GPIO_NOPULL;
	GPIO_InitStruct.Speed = GPIO_SPEED_FREQ_LOW;
	HAL_GPIO_Init(GPIOG, &GPIO_InitStruct);

	/*Configure GPIO pins : I2CFMP1_SCL_Pin I2CFMP_SDA_Pin */
	GPIO_InitStruct.Pin = I2CFMP1_SCL_Pin | I2CFMP_SDA_Pin;
	GPIO_InitStruct.Mode = GPIO_MODE_AF_OD;
	GPIO_InitStruct.Pull = GPIO_PULLUP;
	GPIO_InitStruct.Speed = GPIO_SPEED_FREQ_VERY_HIGH;
	GPIO_InitStruct.Alternate = GPIO_AF4_FMPI2C1;
	HAL_GPIO_Init(GPIOC, &GPIO_InitStruct);

	/*Configure GPIO pin : ARD_D10_Pin */
	GPIO_InitStruct.Pin = ARD_D10_Pin;
	GPIO_InitStruct.Mode = GPIO_MODE_AF_PP;
	GPIO_InitStruct.Pull = GPIO_NOPULL;
	GPIO_InitStruct.Speed = GPIO_SPEED_FREQ_LOW;
	GPIO_InitStruct.Alternate = GPIO_AF1_TIM2;
	HAL_GPIO_Init(ARD_D10_GPIO_Port, &GPIO_InitStruct);

	/*Configure GPIO pins : PG9 PG14 */
	GPIO_InitStruct.Pin = GPIO_PIN_9 | GPIO_PIN_14;
	GPIO_InitStruct.Mode = GPIO_MODE_AF_PP;
	GPIO_InitStruct.Pull = GPIO_NOPULL;
	GPIO_InitStruct.Speed = GPIO_SPEED_FREQ_VERY_HIGH;
	GPIO_InitStruct.Alternate = GPIO_AF8_USART6;
	HAL_GPIO_Init(GPIOG, &GPIO_InitStruct);

	/*Configure GPIO pins : ARD_D12_Pin ARD_D11_Pin */
	GPIO_InitStruct.Pin = ARD_D12_Pin | ARD_D11_Pin;
	GPIO_InitStruct.Mode = GPIO_MODE_AF_PP;
	GPIO_InitStruct.Pull = GPIO_NOPULL;
	GPIO_InitStruct.Speed = GPIO_SPEED_FREQ_VERY_HIGH;
	GPIO_InitStruct.Alternate = GPIO_AF6_SPI3;
	HAL_GPIO_Init(GPIOB, &GPIO_InitStruct);

	/*Configure GPIO pin : ARD_D9_Pin */
	GPIO_InitStruct.Pin = ARD_D9_Pin;
	GPIO_InitStruct.Mode = GPIO_MODE_AF_PP;
	GPIO_InitStruct.Pull = GPIO_NOPULL;
	GPIO_InitStruct.Speed = GPIO_SPEED_FREQ_LOW;
	GPIO_InitStruct.Alternate = GPIO_AF2_TIM4;
	HAL_GPIO_Init(ARD_D9_GPIO_Port, &GPIO_InitStruct);

	/* EXTI interrupt init*/
	HAL_NVIC_SetPriority(EXTI0_IRQn, 0, 0);
	HAL_NVIC_EnableIRQ(EXTI0_IRQn);

}

/* FSMC initialization function */
static void MX_FSMC_Init(void) {

	FSMC_NORSRAM_TimingTypeDef Timing = { 0 };

	/** Perform the SRAM1 memory initialization sequence
	 */
	hsram1.Instance = FSMC_NORSRAM_DEVICE;
	hsram1.Extended = FSMC_NORSRAM_EXTENDED_DEVICE;
	/* hsram1.Init */
	hsram1.Init.NSBank = FSMC_NORSRAM_BANK1;
	hsram1.Init.DataAddressMux = FSMC_DATA_ADDRESS_MUX_DISABLE;
	hsram1.Init.MemoryType = FSMC_MEMORY_TYPE_SRAM;
	hsram1.Init.MemoryDataWidth = FSMC_NORSRAM_MEM_BUS_WIDTH_16;
	hsram1.Init.BurstAccessMode = FSMC_BURST_ACCESS_MODE_DISABLE;
	hsram1.Init.WaitSignalPolarity = FSMC_WAIT_SIGNAL_POLARITY_LOW;
	hsram1.Init.WaitSignalActive = FSMC_WAIT_TIMING_BEFORE_WS;
	hsram1.Init.WriteOperation = FSMC_WRITE_OPERATION_ENABLE;
	hsram1.Init.WaitSignal = FSMC_WAIT_SIGNAL_DISABLE;
	hsram1.Init.ExtendedMode = FSMC_EXTENDED_MODE_DISABLE;
	hsram1.Init.AsynchronousWait = FSMC_ASYNCHRONOUS_WAIT_DISABLE;
	hsram1.Init.WriteBurst = FSMC_WRITE_BURST_DISABLE;
	hsram1.Init.ContinuousClock = FSMC_CONTINUOUS_CLOCK_SYNC_ONLY;
	hsram1.Init.WriteFifo = FSMC_WRITE_FIFO_ENABLE;
	hsram1.Init.PageSize = FSMC_PAGE_SIZE_NONE;
	/* Timing */
	Timing.AddressSetupTime = 15;
	Timing.AddressHoldTime = 15;
	Timing.DataSetupTime = 255;
	Timing.BusTurnAroundDuration = 15;
	Timing.CLKDivision = 16;
	Timing.DataLatency = 17;
	Timing.AccessMode = FSMC_ACCESS_MODE_A;
	/* ExtTiming */

	if (HAL_SRAM_Init(&hsram1, &Timing, NULL) != HAL_OK) {
		Error_Handler();
	}

}

void MetricChangeTask(void *argument) {
	/* init code for USB_HOST */
	MX_USB_HOST_Init();
	/* USER CODE BEGIN 5 */
	const TickType_t xFrequency = METRIC_TASK_RATE;
	TickType_t xLastWakeTime = xTaskGetTickCount();
	/* Infinite loop */
	for (;;) {
		vTaskDelayUntil(&xLastWakeTime, xFrequency);
		long start = xTaskGetTickCount();
		if (metric_change != curr_metric) {
			if (metric_change == 0) {
				//metric is cm
				metric_multiplier = 1;
			} else if (metric_change == 1) {
				//metric is inch
				metric_multiplier = CM_TO_INCH;
			} else if (metric_change == 2) {
				//metric is feet
				metric_multiplier = CM_TO_FEET;
			} else if (metric_change == 3) {
				//metric is meter
				metric_multiplier = CM_TO_METER;
			}
			curr_metric = metric_change;
		}
		long stop = xTaskGetTickCount() - start;
		osDelay(1);
	}
	/* USER CODE END 5 */
}

void MotorTask(void *argument) {
	/* USER CODE BEGIN MotorTask */
	MX_USB_HOST_Init();
	HAL_TIM_PWM_Start(&htim3, TIM_CHANNEL_3);
	HAL_TIM_PWM_Start(&htim5, TIM_CHANNEL_4);
	HAL_GPIO_WritePin(GPIOB, GPIO_PIN_6, GPIO_PIN_RESET);
	HAL_GPIO_WritePin(GPIOE, GPIO_PIN_6, GPIO_PIN_RESET);
	HAL_GPIO_WritePin(GPIOC, GPIO_PIN_13, GPIO_PIN_RESET);
	HAL_GPIO_WritePin(GPIOA, GPIO_PIN_4, GPIO_PIN_RESET);
	HAL_GPIO_WritePin(GPIOB, GPIO_PIN_0, GPIO_PIN_RESET);
	HAL_GPIO_WritePin(GPIOF, GPIO_PIN_10, GPIO_PIN_RESET);
	const TickType_t xFrequency = MOTOR_TASK_RATE;
	TickType_t xLastWakeTime = xTaskGetTickCount();
	/* Infinite loop */
	for (;;) {
		vTaskDelayUntil(&xLastWakeTime, xFrequency);
		long start = xTaskGetTickCount();
		if (distance_high > 0) {
			HAL_GPIO_WritePin(GPIOB, GPIO_PIN_6, GPIO_PIN_RESET);
			HAL_GPIO_WritePin(GPIOE, GPIO_PIN_6, GPIO_PIN_SET);
			HAL_GPIO_WritePin(GPIOC, GPIO_PIN_13, GPIO_PIN_RESET);
			HAL_GPIO_WritePin(GPIOA, GPIO_PIN_4, GPIO_PIN_SET);

			__HAL_TIM_SET_COMPARE(&htim3, TIM_CHANNEL_3, 850);
			__HAL_TIM_SET_COMPARE(&htim5, TIM_CHANNEL_4, 850);
		} else if (distance_low > 150) {
			__HAL_TIM_SET_COMPARE(&htim3, TIM_CHANNEL_3, distance_low * 3);
			__HAL_TIM_SET_COMPARE(&htim5, TIM_CHANNEL_4, distance_low * 3);

			HAL_GPIO_WritePin(GPIOB, GPIO_PIN_6, GPIO_PIN_RESET);
			HAL_GPIO_WritePin(GPIOE, GPIO_PIN_6, GPIO_PIN_SET);
			HAL_GPIO_WritePin(GPIOC, GPIO_PIN_13, GPIO_PIN_RESET);
			HAL_GPIO_WritePin(GPIOA, GPIO_PIN_4, GPIO_PIN_SET);
		} else if (distance_low > 50) {
			HAL_GPIO_WritePin(GPIOB, GPIO_PIN_6, GPIO_PIN_RESET);
			HAL_GPIO_WritePin(GPIOE, GPIO_PIN_6, GPIO_PIN_SET);
			HAL_GPIO_WritePin(GPIOC, GPIO_PIN_13, GPIO_PIN_RESET);
			HAL_GPIO_WritePin(GPIOA, GPIO_PIN_4, GPIO_PIN_SET);

			__HAL_TIM_SET_COMPARE(&htim3, TIM_CHANNEL_3, distance_low * 3.5);
			__HAL_TIM_SET_COMPARE(&htim5, TIM_CHANNEL_4, distance_low * 3.5);
		} else {
			HAL_GPIO_WritePin(GPIOB, GPIO_PIN_6, GPIO_PIN_RESET);
			HAL_GPIO_WritePin(GPIOE, GPIO_PIN_6, GPIO_PIN_SET);
			HAL_GPIO_WritePin(GPIOC, GPIO_PIN_13, GPIO_PIN_RESET);
			HAL_GPIO_WritePin(GPIOA, GPIO_PIN_4, GPIO_PIN_RESET);

			__HAL_TIM_SET_COMPARE(&htim3, TIM_CHANNEL_3, 500);
			__HAL_TIM_SET_COMPARE(&htim5, TIM_CHANNEL_4, 500);

			// Pseudocode for turning and calculating area
			// At the beginning, before starting to move, get the distance and store into a variable
			// Then move until a certain threshold
			// Once at the wall, turn 90 degrees to face the next wall
			// Then repeat the steps, before moving, get distance and store into variable
			// At the beginning of each turn check a turn counter to see if 3 turns have been performed.
			// If turn counter is 3, calculate area, if it is less than 3 then continue like normal
		}
		long stop = xTaskGetTickCount() - start;
		osDelay(1);
	}
	/* USER CODE END MotorTask */
}

void LidarTask(void *argument) {
	/* USER CODE BEGIN LidarTask */
	const TickType_t xFrequency = LIDAR_TASK_RATE;
	TickType_t xLastWakeTime = xTaskGetTickCount();
	/* Infinite loop */
	for (;;) {
		vTaskDelayUntil(&xLastWakeTime, xFrequency);
		long start = xTaskGetTickCount();
		HAL_StatusTypeDef status = HAL_UART_GetState(&huart7);
		// send 5A 04 04 00 to tell lidar sensor to send data
		HAL_StatusTypeDef statusT = HAL_UART_Transmit(&huart7, lidar_tx_buffer, 4, 25);

		//get 9 bytes of data and place into buffer
		HAL_StatusTypeDef statusR = HAL_UART_Receive_DMA(&huart7, lidar_rx_buffer, 9);
		if (lidar_rx_buffer[0] == 89 && lidar_rx_buffer[1] == 89) {
			distance_high = lidar_rx_buffer[3];
			distance_low = lidar_rx_buffer[2];
		}
		long stop = xTaskGetTickCount() - start;
		osDelay(1);
	}
	/* USER CODE END LidarTask */
}

void LCDTask(void *argument) {
	/* USER CODE BEGIN LCDTask */
	const TickType_t xFrequency = LCD_TASK_RATE;
	TickType_t xLastWakeTime = xTaskGetTickCount();
	/* Infinite loop */
	for (;;) {
		vTaskDelayUntil(&xLastWakeTime, xFrequency);
		long start = xTaskGetTickCount();
		char num_string[30] = { 0 };
		char string_high[15] = { 0 };
		char string_low[15] = { 0 };
		if (curr_metric == 0) {
			metric[0] = '\0';
			strcpy(metric, " cm   ");
		} else if (curr_metric == 1) {
			metric[0] = '\0';
			strcpy(metric, " inch   ");
		}
		if (curr_metric == 2) {
			metric[0] = '\0';
			strcpy(metric, " ft   ");
		}
		if (curr_metric == 3) {
			metric[0] = '\0';
			strcpy(metric, " meter  ");
		}
		uint16_t temp = metric_multiplier
				* (distance_high * 255 + distance_low);

		itoa(temp, string_high, 10);
		strcat(num_string, string_high);
		strcat(num_string, metric);
		BSP_LCD_SetTextColor(LCD_COLOR_WHITE);
		BSP_LCD_FillRect(0, 112, 240, 15);
		BSP_LCD_SetTextColor(LCD_COLOR_BLACK);
		BSP_LCD_DisplayStringAt(0, 112, num_string, CENTER_MODE);
		long stop = xTaskGetTickCount() - start;
		osDelay(1);
	}
	/* USER CODE END LCDTask */
}

void HAL_TIM_PeriodElapsedCallback(TIM_HandleTypeDef *htim) {
	if (htim->Instance == TIM6) {
		HAL_IncTick();
	}
}

void Error_Handler(void) {
}

/************************ (C) COPYRIGHT STMicroelectronics *****END OF FILE****/
